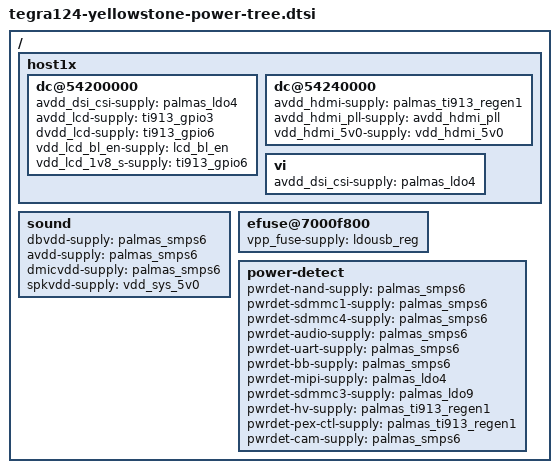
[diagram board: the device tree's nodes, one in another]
/*
 * arch/arm/boot/dts/tegra124-platforms/tegra124-tn8-power-tree-e1936-1000-a03.dtsi
 *
 * Copyright (c) 2014-2015, NVIDIA CORPORATION.  All rights reserved.
 *
 * This program is free software; you can redistribute it and/or modify
 * it under the terms of the GNU General Public License as published by
 * the Free Software Foundation; either version 2 of the License, or
 * (at your option) any later version.
 *
 * This program is distributed in the hope that it will be useful, but WITHOUT
 * ANY WARRANTY; without even the implied warranty of MERCHANTABILITY or
 * FITNESS FOR A PARTICULAR PURPOSE.  See the GNU General Public License for
 * more details.
 *
 * You should have received a copy of the GNU General Public License along
 * with this program; if not, write to the Free Software Foundation, Inc.,
 * 51 Franklin Street, Fifth Floor, Boston, MA  02110-1301, USA.
 */

#include "tegra124-yellowstone-pmic.dtsi"
#include "tegra124-yellowstone-fixed.dtsi"

/ {
	host1x {
		/* tegradc.0 */
		dc@54200000 {
			avdd_dsi_csi-supply = <&palmas_ldo4>;
			avdd_lcd-supply = <&ti913_gpio3>;
			dvdd_lcd-supply = <&ti913_gpio6>;
			vdd_lcd_bl_en-supply = <&lcd_bl_en>;
			vdd_lcd_1v8_s-supply = <&ti913_gpio6>;
		};
		/* tegradc.1 */
		dc@54240000 {
			avdd_hdmi-supply = <&palmas_ti913_regen1>;
			avdd_hdmi_pll-supply = <&avdd_hdmi_pll>;
			vdd_hdmi_5v0-supply = <&vdd_hdmi_5v0>;
		};
		vi {
			avdd_dsi_csi-supply = <&palmas_ldo4>;
		};
	};

	sound {
		dbvdd-supply = <&palmas_smps6>;
		avdd-supply = <&palmas_smps6>;
		dmicvdd-supply = <&palmas_smps6>;
		spkvdd-supply = <&vdd_sys_5v0>;
	};

	/* Populate fuse supply */
	efuse@7000f800 {
		vpp_fuse-supply = <&ldousb_reg>;
	};

	power-detect {
		pwrdet-nand-supply = <&palmas_smps6>;
		pwrdet-sdmmc1-supply = <&palmas_smps6>;
		pwrdet-sdmmc4-supply = <&palmas_smps6>;
		pwrdet-audio-supply = <&palmas_smps6>;
		pwrdet-uart-supply = <&palmas_smps6>;
		pwrdet-bb-supply = <&palmas_smps6>;
		pwrdet-mipi-supply = <&palmas_ldo4>;
		pwrdet-sdmmc3-supply = <&palmas_ldo9>;
		pwrdet-hv-supply = <&palmas_ti913_regen1>;
		pwrdet-pex-ctl-supply = <&palmas_ti913_regen1>;
		pwrdet-cam-supply = <&palmas_smps6>;
	};
/*
	udc@7d000000 {
		avdd_usb-supply = <&palmas_ti913_regen1>;
		avdd_pll_utmip-supply = <&palmas_smps6>;
	};

	otg@7d000000 {
		usb_vbus-supply = <&usb0_vbus>;
	};
*/
};
